# HDSC_HC32F472 register map
Vendor: HDSC; Series: ARMCM4; File version: 1.0
CPU: CM4 r0p1, little endian, MPU, FPU, 4 interrupt priority bits
Registers are 32-bit, read-write, reset 0x0 unless marked. A register's access mark holds for its fields unless they carry their own. Offsets are from the block's base; [hi:lo] are bit positions; {n}, {i} and the like mark numbered series.

## CMU
Base 0x40048000
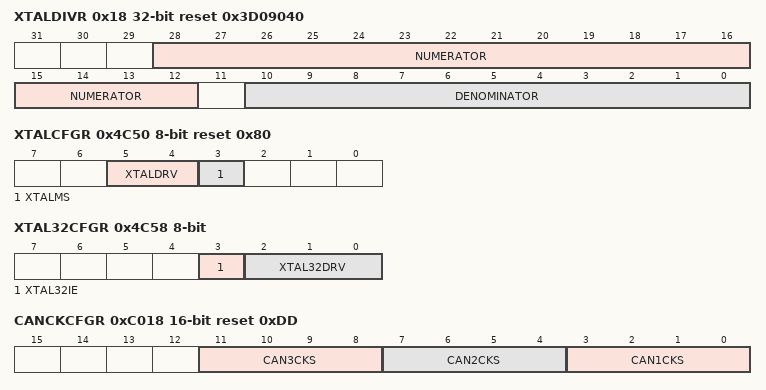
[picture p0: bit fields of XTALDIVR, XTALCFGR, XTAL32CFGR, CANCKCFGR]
0x18 XTALDIVR reset 0x3D09040
  [28:12] NUMERATOR, [10:0] DENOMINATOR
0x1C XTALDIVCR
  [0] FRADIVEN
0x4C50 XTALCFGR 8-bit reset 0x80
  [5:4] XTALDRV, [3] XTALMS
0x4C54 XTAL32CR 8-bit
  [0] XTAL32STP
0x4C58 XTAL32CFGR 8-bit
  [3] XTAL32IE, [2:0] XTAL32DRV
0x4C68 XTAL32NFR 8-bit
  [1:0] XTAL32NF
0x4C6C LRCCR 8-bit
  [0] LRCSTP
0x4C74 LRCTRM 8-bit
0xC010 PERICKSEL 16-bit
  [3:0] PERICKSEL
0xC018 CANCKCFGR 16-bit reset 0xDD
  [11:8] CAN3CKS, [7:4] CAN2CKS, [3:0] CAN1CKS
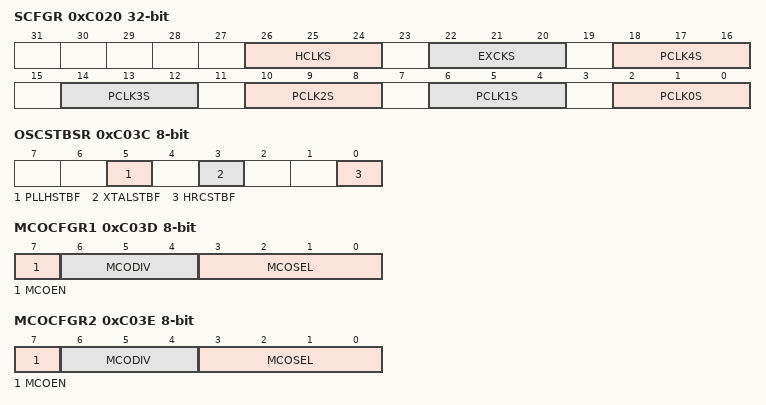
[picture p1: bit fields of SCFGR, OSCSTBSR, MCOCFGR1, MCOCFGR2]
0xC020 SCFGR
  [26:24] HCLKS, [22:20] EXCKS, [4n+2:4n] PCLK{n}S (n=0..4)
0xC024 USBCKCFGR 8-bit reset 0x40
  [7:4] USBCKS
0xC026 CKSWR 8-bit reset 0x1
  [2:0] CKSW
0xC02A PLLHCR 8-bit reset 0x1
  [0] PLLHOFF
0xC032 XTALCR 8-bit reset 0x1
  [0] XTALSTP
0xC036 HRCCR 8-bit reset 0x1
  [0] HRCSTP
0xC038 MRCCR 8-bit reset 0x80
  [0] MRCSTP
0xC03C OSCSTBSR 8-bit
  [5] PLLHSTBF, [3] XTALSTBF, [0] HRCSTBF
0xC03D MCOCFGR1 8-bit
  [7] MCOEN, [6:4] MCODIV, [3:0] MCOSEL
0xC03E MCOCFGR2 8-bit
  [7] MCOEN, [6:4] MCODIV, [3:0] MCOSEL
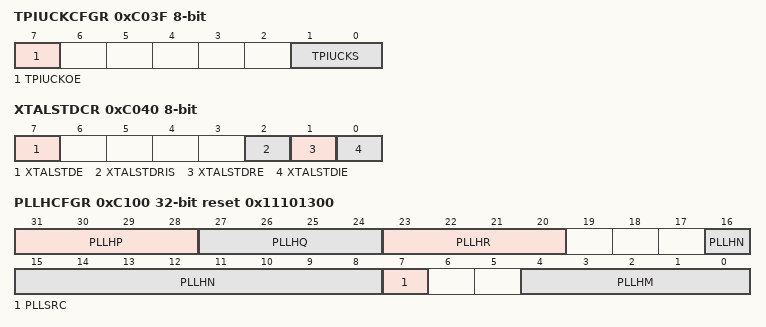
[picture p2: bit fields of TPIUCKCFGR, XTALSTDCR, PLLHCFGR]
0xC03F TPIUCKCFGR 8-bit
  [7] TPIUCKOE, [1:0] TPIUCKS
0xC040 XTALSTDCR 8-bit
  [7] XTALSTDE, [2] XTALSTDRIS, [1] XTALSTDRE, [0] XTALSTDIE
0xC041 XTALSTDSR 8-bit
  [0] XTALSTDF
0xC061 MRCTRM 8-bit
0xC062 HRCTRM 8-bit
0xC0A2 XTALSTBCR 8-bit reset 0x5
  [3:0] XTALSTB
0xC100 PLLHCFGR reset 0x11101300
  [31:28] PLLHP, [27:24] PLLHQ, [23:20] PLLHR, [16:8] PLLHN, [7] PLLSRC, [4:0] PLLHM

## CRC
Base 0x40008C00
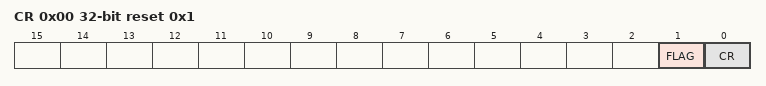
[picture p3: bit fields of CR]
0x00 CR reset 0x1
  [1] FLAG ro, [0] CR
0x04 RESLT
{0x80+4i} DAT{i} (i=0..31)

## CTC
Base 0x40049C00
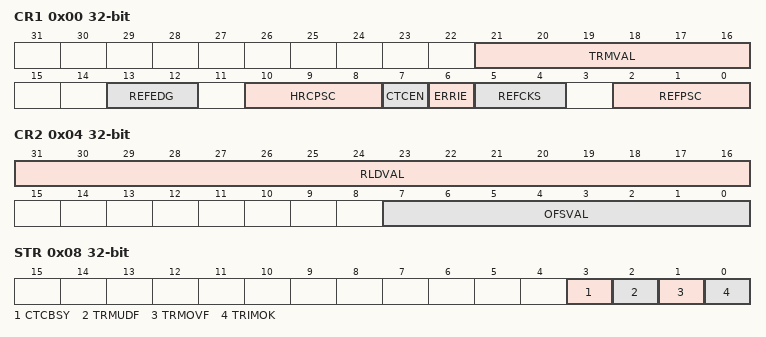
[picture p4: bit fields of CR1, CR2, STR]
0x00 CR1
  [21:16] TRMVAL, [13:12] REFEDG, [10:8] HRCPSC, [7] CTCEN, [6] ERRIE, [5:4] REFCKS, [2:0] REFPSC
0x04 CR2
  [31:16] RLDVAL, [7:0] OFSVAL
0x08 STR ro
  [3] CTCBSY, [2] TRMUDF, [1] TRMOVF, [0] TRIMOK
0x0C CNT 16-bit ro
  [15:0] CTCCNT

## DAC1 — desc DAC
Base 0x40041000
Same registers: DAC2 0x40041400, DAC3 0x40041800, DAC4 0x40041C00
0x00 DADR1 16-bit
0x02 DADR2 16-bit
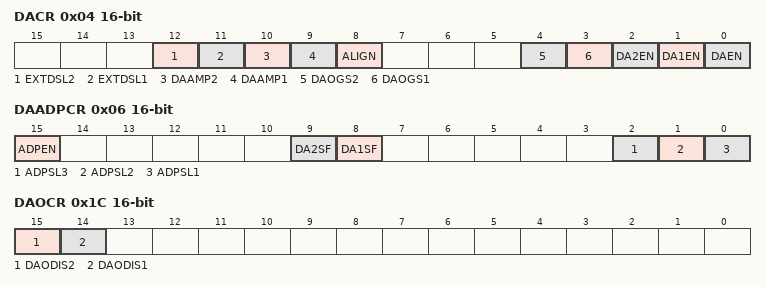
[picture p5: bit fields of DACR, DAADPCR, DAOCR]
0x04 DACR 16-bit
  [12] EXTDSL2, [11] EXTDSL1, [10] DAAMP2, [9] DAAMP1, [8] ALIGN, [4] DAOGS2, [3] DAOGS1, [2] DA2EN, [1] DA1EN, [0] DAEN
0x06 DAADPCR 16-bit
  [15] ADPEN, [9] DA2SF ro, [8] DA1SF ro, [2] ADPSL3, [1] ADPSL2, [0] ADPSL1
0x1C DAOCR 16-bit
  [15] DAODIS2, [14] DAODIS1

## DBGC
Base 0xE0042000
{0x0+4i} AUTHID{i} (i=0..2)
0x0C CHIPID reset 0x48440682
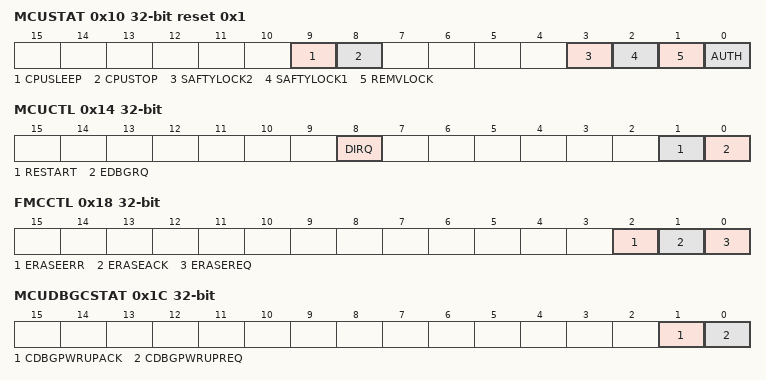
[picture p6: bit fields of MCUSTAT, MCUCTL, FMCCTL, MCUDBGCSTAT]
0x10 MCUSTAT reset 0x1
  [9] CPUSLEEP, [8] CPUSTOP, [3] SAFTYLOCK2, [2] SAFTYLOCK1, [1] REMVLOCK, [0] AUTH
0x14 MCUCTL
  [8] DIRQ, [1] RESTART, [0] EDBGRQ
0x18 FMCCTL
  [2] ERASEERR, [1] ERASEACK, [0] ERASEREQ
0x1C MCUDBGCSTAT
  [1] CDBGPWRUPACK, [0] CDBGPWRUPREQ
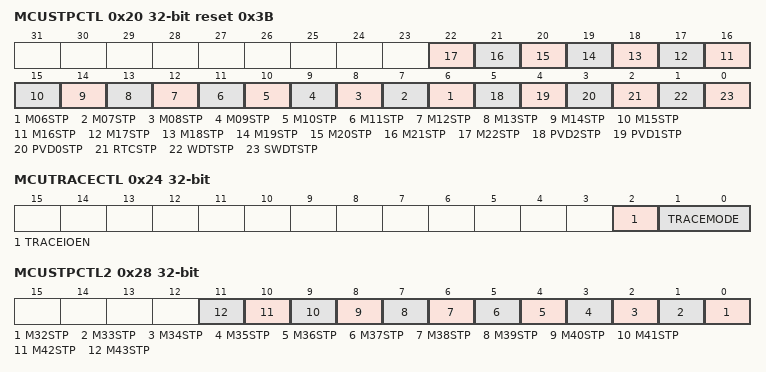
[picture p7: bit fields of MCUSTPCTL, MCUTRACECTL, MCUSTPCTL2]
0x20 MCUSTPCTL reset 0x3B
  [n] M{n:02}STP (n=6..22), [5] PVD2STP, [4] PVD1STP, [3] PVD0STP, [2] RTCSTP, [1] WDTSTP, [0] SWDTSTP
0x24 MCUTRACECTL
  [2] TRACEIOEN, [1:0] TRACEMODE
0x28 MCUSTPCTL2
  [n-32] M{n}STP (n=32..43)

## DCU1 — desc DCU
Base 0x40056000
Same registers: DCU2 0x40056400, DCU3 0x40056800
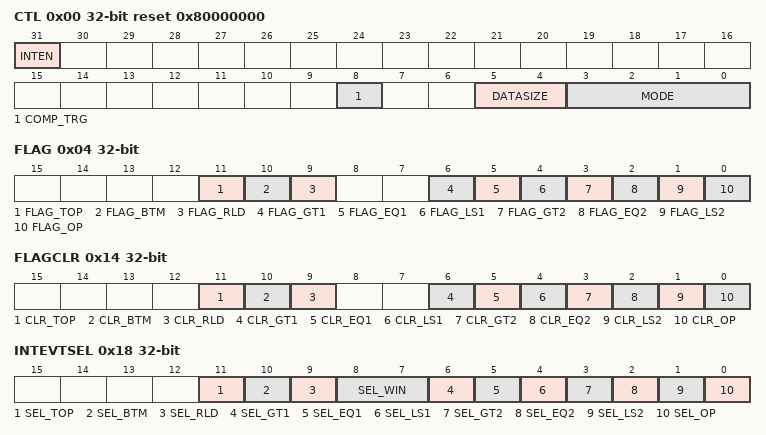
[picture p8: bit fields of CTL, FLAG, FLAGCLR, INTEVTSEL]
0x00 CTL reset 0x80000000
  [31] INTEN, [8] COMP_TRG, [5:4] DATASIZE, [3:0] MODE
0x04 FLAG ro
  [11] FLAG_TOP, [10] FLAG_BTM, [9] FLAG_RLD, [6] FLAG_GT1, [5] FLAG_EQ1, [4] FLAG_LS1, [3] FLAG_GT2, [2] FLAG_EQ2, [1] FLAG_LS2, [0] FLAG_OP
{0x8+4i} DATA{i} (i=0..2)
0x14 FLAGCLR wo
  [11] CLR_TOP rw, [10] CLR_BTM rw, [9] CLR_RLD rw, [6] CLR_GT1, [5] CLR_EQ1, [4] CLR_LS1, [3] CLR_GT2, [2] CLR_EQ2, [1] CLR_LS2, [0] CLR_OP
0x18 INTEVTSEL
  [11] SEL_TOP, [10] SEL_BTM, [9] SEL_RLD, [8:7] SEL_WIN, [6] SEL_GT1, [5] SEL_EQ1, [4] SEL_LS1, [3] SEL_GT2, [2] SEL_EQ2, [1] SEL_LS2, [0] SEL_OP

## DMA1 — desc DMA
Base 0x40053000
Same registers: DMA2 0x40053400
0x00 EN
  [0] EN
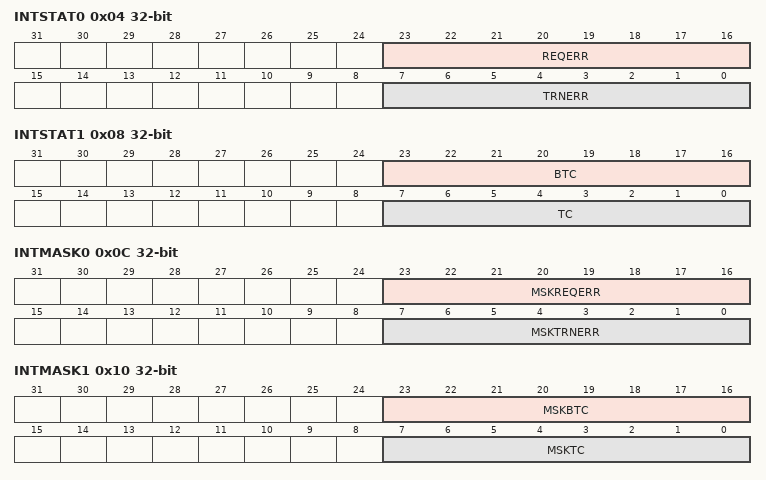
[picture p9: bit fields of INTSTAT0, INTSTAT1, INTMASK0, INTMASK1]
0x04 INTSTAT0 ro
  [23:16] REQERR, [7:0] TRNERR
0x08 INTSTAT1 ro
  [23:16] BTC, [7:0] TC
0x0C INTMASK0
  [23:16] MSKREQERR, [7:0] MSKTRNERR
0x10 INTMASK1
  [23:16] MSKBTC, [7:0] MSKTC
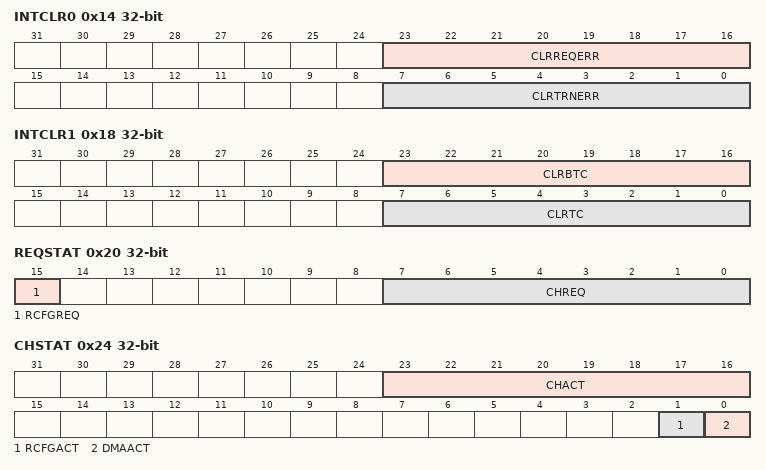
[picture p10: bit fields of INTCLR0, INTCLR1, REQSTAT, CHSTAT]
0x14 INTCLR0
  [23:16] CLRREQERR, [7:0] CLRTRNERR
0x18 INTCLR1
  [23:16] CLRBTC, [7:0] CLRTC
0x1C CHEN
  [7:0] CHEN
0x20 REQSTAT ro
  [15] RCFGREQ, [7:0] CHREQ
0x24 CHSTAT ro
  [23:16] CHACT, [1] RCFGACT, [0] DMAACT
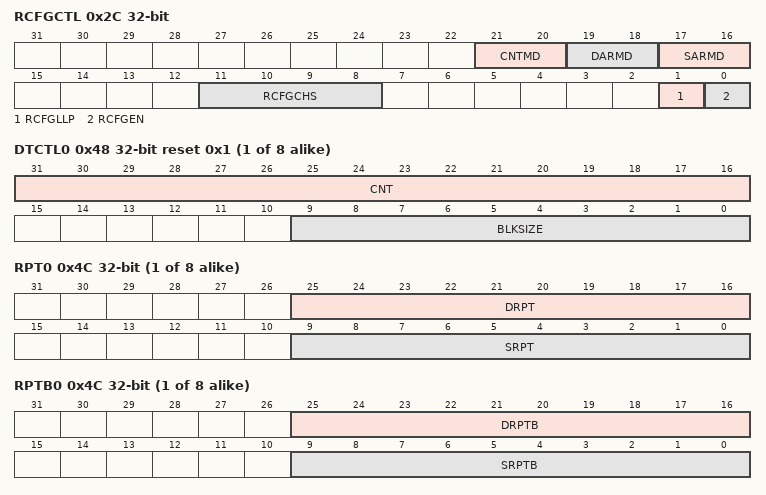
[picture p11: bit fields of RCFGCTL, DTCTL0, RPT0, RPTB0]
0x2C RCFGCTL
  [21:20] CNTMD, [19:18] DARMD, [17:16] SARMD, [11:8] RCFGCHS, [1] RCFGLLP, [0] RCFGEN
0x34 CHENCLR
  [7:0] CHENCLR
{0x40+0x40*i} SAR{i} (i=0..7)
{0x44+0x40*i} DAR{i} (i=0..7)
{0x48+0x40*i} DTCTL{i} reset 0x1 (i=0..7)
  [31:16] CNT, [9:0] BLKSIZE
{0x4C+0x40*i} RPT{i} (i=0..7)
  [25:16] DRPT, [9:0] SRPT
{0x4C+0x40*i} RPTB{i} (i=0..7)
  [25:16] DRPTB, [9:0] SRPTB
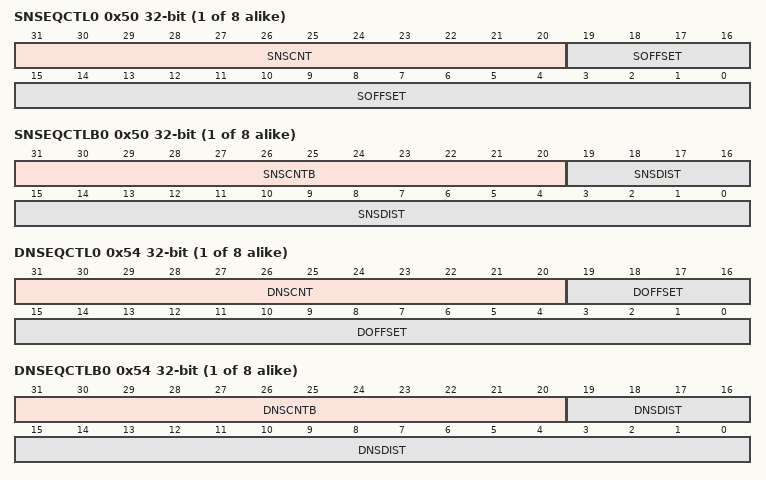
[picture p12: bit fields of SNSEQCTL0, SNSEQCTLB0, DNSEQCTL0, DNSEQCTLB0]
{0x50+0x40*i} SNSEQCTL{i} (i=0..7)
  [31:20] SNSCNT, [19:0] SOFFSET
{0x50+0x40*i} SNSEQCTLB{i} (i=0..7)
  [31:20] SNSCNTB, [19:0] SNSDIST
{0x54+0x40*i} DNSEQCTL{i} (i=0..7)
  [31:20] DNSCNT, [19:0] DOFFSET
{0x54+0x40*i} DNSEQCTLB{i} (i=0..7)
  [31:20] DNSCNTB, [19:0] DNSDIST
{0x58+0x40*i} LLP{i} (i=0..7)
  [31:2] LLP
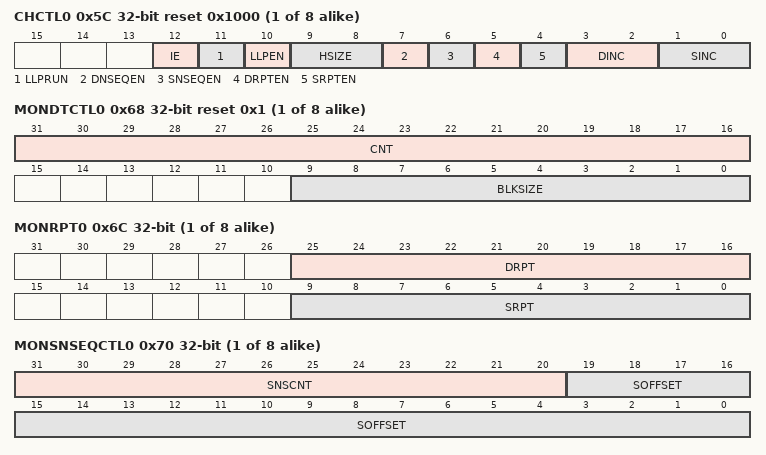
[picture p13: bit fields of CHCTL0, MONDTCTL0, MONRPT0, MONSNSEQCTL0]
{0x5C+0x40*i} CHCTL{i} reset 0x1000 (i=0..7)
  [12] IE, [11] LLPRUN, [10] LLPEN, [9:8] HSIZE, [7] DNSEQEN, [6] SNSEQEN, [5] DRPTEN, [4] SRPTEN, [3:2] DINC, [1:0] SINC
{0x60+0x40*i} MONSAR{i} ro (i=0..7)
{0x64+0x40*i} MONDAR{i} ro (i=0..7)
{0x68+0x40*i} MONDTCTL{i} ro reset 0x1 (i=0..7)
  [31:16] CNT, [9:0] BLKSIZE
{0x6C+0x40*i} MONRPT{i} ro (i=0..7)
  [25:16] DRPT, [9:0] SRPT
{0x70+0x40*i} MONSNSEQCTL{i} ro (i=0..7)
  [31:20] SNSCNT, [19:0] SOFFSET
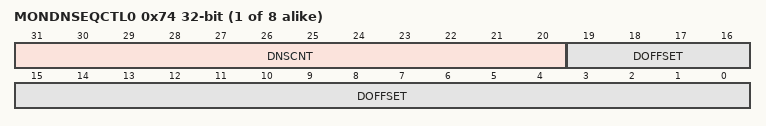
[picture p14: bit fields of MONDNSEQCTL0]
{0x74+0x40*i} MONDNSEQCTL{i} ro (i=0..7)
  [31:20] DNSCNT, [19:0] DOFFSET
